# STM32WBA54xx register map
File version: 1.0
Registers are 32-bit, read-write, reset 0x0 unless marked. A register's access mark holds for its fields unless they carry their own. Offsets are from the block's base; [hi:lo] are bit positions; {n}, {i} and the like mark numbered series.

## HASH
Base 0x420C0400
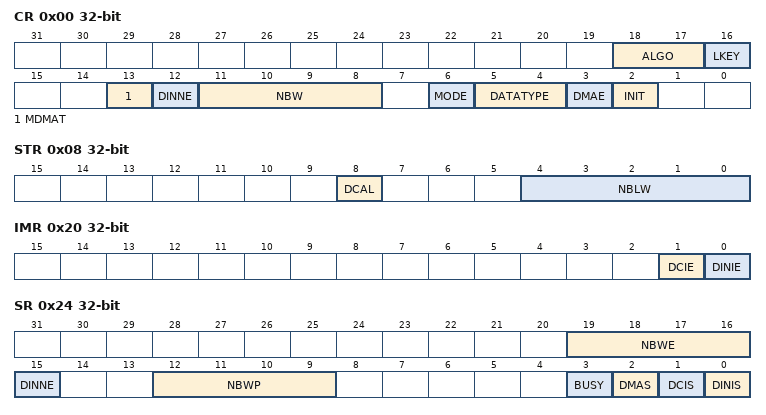
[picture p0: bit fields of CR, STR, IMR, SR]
0x00 CR — HASH control register
  [18:17] ALGO, [16] LKEY, [13] MDMAT, [12] DINNE, [11:8] NBW, [6] MODE, [5:4] DATATYPE, [3] DMAE, [2] INIT
0x04 DIN — HASH data input register
0x08 STR — HASH start register
  [8] DCAL, [4:0] NBLW
{0xC+4i} HR{i} (i=0..4) — HASH digest registers
0x20 IMR — HASH interrupt enable register
  [1] DCIE, [0] DINIE
0x24 SR — HASH status register
  [19:16] NBWE, [15] DINNE, [12:9] NBWP, [3] BUSY, [2] DMAS, [1] DCIS, [0] DINIS
{0xF8+4i} CSR{i} (i=0..53) — HASH context swap registers
{0x310+4i} DIGEST_HR{i} (i=0..7) — HASH digest registers

## RNG
Base 0x420C0800
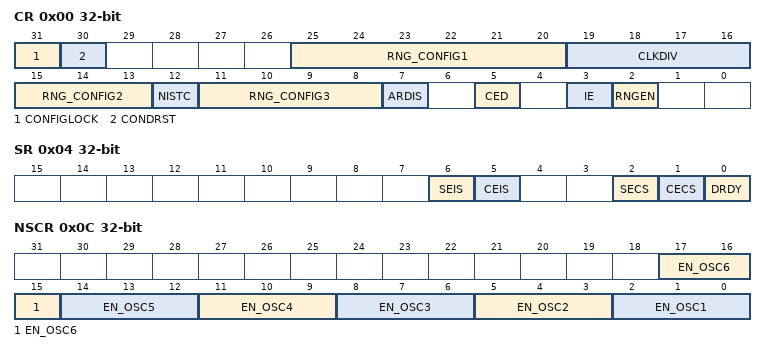
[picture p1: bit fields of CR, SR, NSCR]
0x00 CR — RNG control register
  [31] CONFIGLOCK — RNG configuration lock
  [30] CONDRST — Conditioning soft reset
  [25:20] RNG_CONFIG1 — RNG configuration 1
  [19:16] CLKDIV — Clock divider factor
    0=BY_1 (No clock division); 1=BY_2 (2 RNG clock cycles per internal RNG clock); 2=BY_4 (4 RNG clock cycles per internal RNG clock); 3=BY_8 (8 RNG clock cycles per internal RNG clock); 4=BY_16 (16 RNG clock cycles per internal RNG clock); 5=BY_32 (32 RNG clock cycles per internal RNG clock); 6=BY_64 (64 RNG clock cycles per internal RNG clock); 7=BY_128 (128 RNG clock cycles per internal RNG clock); 8=BY_256 (256 RNG clock cycles per internal RNG clock); 9=BY_512 (512 RNG clock cycles per internal RNG clock); 10=BY_1024 (1024 RNG clock cycles per internal RNG clock); 11=BY_2048 (2048 RNG clock cycles per internal RNG clock); 12=BY_4096 (4096 RNG clock cycles per internal RNG clock); 13=BY_8192 (8192 RNG clock cycles per internal RNG clock); 14=BY_16384 (16384 RNG clock cycles per internal RNG clock); 15=BY_32768 (32768 RNG clock cycles per internal RNG clock)
  [15:13] RNG_CONFIG2 — RNG configuration 2
  [12] NISTC — NIST custom
  [11:8] RNG_CONFIG3 — RNG configuration 3
  [7] ARDIS — Auto reset disable
  [5] CED — Clock error detection
  [3] IE — Interrupt enable
  [2] RNGEN — True random number generator enable
0x04 SR — RNG status register
  [6] SEIS, [5] CEIS, [2] SECS, [1] CECS, [0] DRDY
0x08 DR — RNG data register
  [31:0] RNDATA
0x0C NSCR — RNG noise source control register
  [17:15] EN_OSC6 — EN_OSC6[2:0] bits (Each bit drives one oscillator enable signal input of instance number 3, gated with RNGEN bit in RNG_CR (set bit to enable the oscillator). Bit is ignored otherwise.)
  [14:12] EN_OSC5 — EN_OSC5[2:0] bits (Each bit drives one oscillator enable signal input of instance number 2, gated with RNGEN bit in RNG_CR (set bit to enable the oscillator). Bit is ignored otherwise.)
  [11:9] EN_OSC4 — EN_OSC4[2:0] bits (Each bit drives one oscillator enable signal input of instance number 1, gated with RNGEN bit in RNG_CR (set bit to enable the oscillator). Bit is ignored otherwise.)
  [8:6] EN_OSC3 — EN_OSC3[2:0] bits (Each bit drives one oscillator enable signal input of instance number 3, gated with RNGEN bit in RNG_CR (set bit to enable the oscillator). Bit is ignored otherwise.)
  [5:3] EN_OSC2 — EN_OSC2[2:0] bits (Each bit drives one oscillator enable signal input of instance number 2, gated with RNGEN bit in RNG_CR (set bit to enable the oscillator). Bit is ignored otherwise.)
  [2:0] EN_OSC1 — EN_OSC1[2:0] bits (Each bit drives one oscillator enable signal input of instance number 1, gated with RNGEN bit in RNG_CR (set bit to enable the oscillator). Bit is ignored otherwise.)
0x10 HTCR — RNG health test configuration register
  [31:0] HTCFG

## HSEM — HW Semaphore HSEM
Base 0x420C1C00
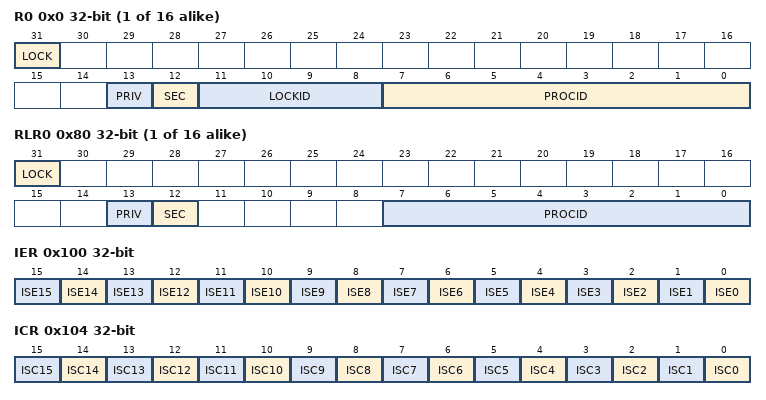
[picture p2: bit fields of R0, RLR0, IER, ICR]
{0x0+4i} R{i} (i=0..15) — HSEM 2-step write lock and read back registers
  [31] LOCK — Lock indication
  [13] PRIV — Semaphore privilege bit
  [12] SEC — Semaphore secure bit
  [11:8] LOCKID — Semaphore LockID
    0=NONE; 2=CPU1
  [7:0] PROCID — Semaphore ProcessID
{0x80+4i} RLR{i} (i=0..15) — HSEM 1-step read lock registers
  [31] LOCK — Lock indication
  [13] PRIV — Semaphore privilege bit
  [12] SEC — Semaphore secure bit
  [7:0] PROCID — Semaphore ProcessID
0x100 IER — HSEM interrupt enable register
  [n] ISE{n} (n=0..15) — semaphore {n} interrupt enable bit
0x104 ICR — HSEM interrupt clear register
  [n] ISC{n} (n=0..15) — semaphore {n} interrupt clear bit
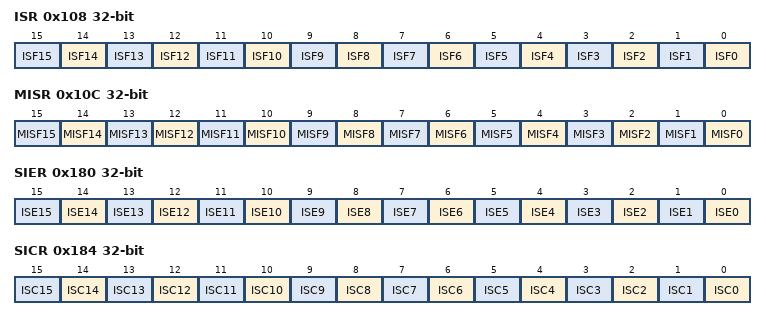
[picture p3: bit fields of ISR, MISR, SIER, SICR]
0x108 ISR — HSEM interrupt status register
  [n] ISF{n} (n=0..15) — semaphore {n} interrupt status bit
0x10C MISR — HSEM masked interrupt status register
  [n] MISF{n} (n=0..15) — semaphore {n} interrupt masked status bit
0x180 SIER — HSEM secure interrupt enable register
  [n] ISE{n} (n=0..15) — semaphore {n} secure interrupt enable bit
0x184 SICR — HSEM secure interrupt clear register
  [n] ISC{n} (n=0..15) — semaphore {n} secure interrupt clear bit
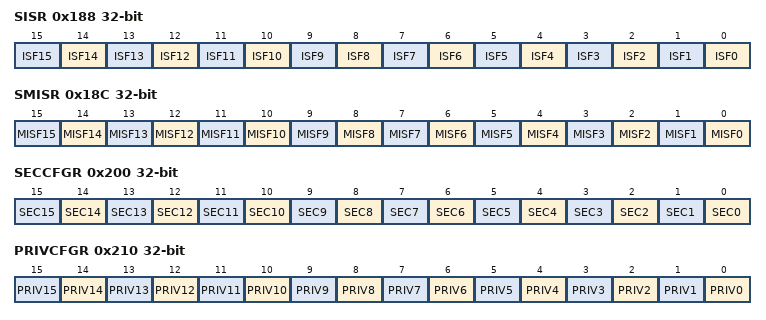
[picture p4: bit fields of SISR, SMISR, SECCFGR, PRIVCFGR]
0x188 SISR — HSEM secure interrupt status register
  [n] ISF{n} (n=0..15) — semaphore {n} secure interrupt status bit
0x18C SMISR — HSEM secure masked interrupt status register
  [n] MISF{n} (n=0..15) — semaphore {n} secure interrupt masked status bit
0x200 SECCFGR — HSEM security configuration register
  [n] SEC{n} (n=0..15) — semaphore {n} secure attribute status bit
0x210 PRIVCFGR — HSEM privilege configuration register
  [n] PRIV{n} (n=0..15) — semaphore {n} privilege attribute status bit
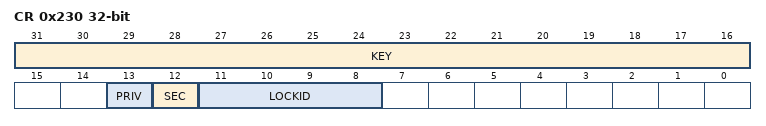
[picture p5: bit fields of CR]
0x230 CR — HSEM Semaphore clear register
  [31:16] KEY — semaphores clear key
  [13] PRIV — PRIV value of semaphores to be cleared
  [12] SEC
  [11:8] LOCKID — LOCKID of semaphores to be cleared
0x234 KEYR — HSEM Semaphore clear key register
  [31:16] KEY — semaphores clear key
